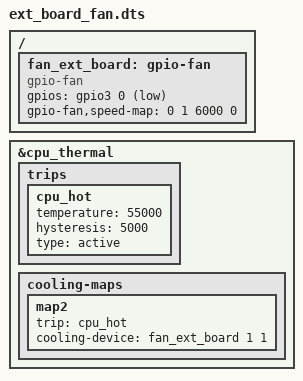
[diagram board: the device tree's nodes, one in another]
/dts-v1/;
/plugin/;

/ {
    fragment@0 {
        target-path = "/";
        __overlay__ {
            fan_ext_board: gpio-fan {
                compatible = "gpio-fan";
                #cooling-cells = <2>;
                gpios = <&gpio3 0 1>;
                gpio-fan,speed-map = <0 1 6000 0>;
                status = "okay";
            };
        };
    };
    fragment@1 {
        target = <&cpu_thermal>;
        __overlay__ {
            trips {
                cpu_hot: cpu_hot {
                        temperature = <55000>;
                        hysteresis = <5000>;
                        type = "active";
                };
            };
            cooling-maps {
                map2 {
                        trip = <&cpu_hot>;
                        cooling-device = <&fan_ext_board 1 1>;
                };
            };
        };
    };
};
